VERSION ""
NS_ :

BS_:

BU_: Controls

BO_ 1408 CONTROL_MODE: 1 Controls
  SG_ State_name : 0|8@1- (1,0) [0|255] "" Controls

BO_ 1410 Motor_Precharge_Enable: 1 Controls
  SG_ Motor_Precharge_enable : 0|8@1+ (1,0) [0|255] "" Controls

BO_ 1408 Control_Mode: 1 Controls

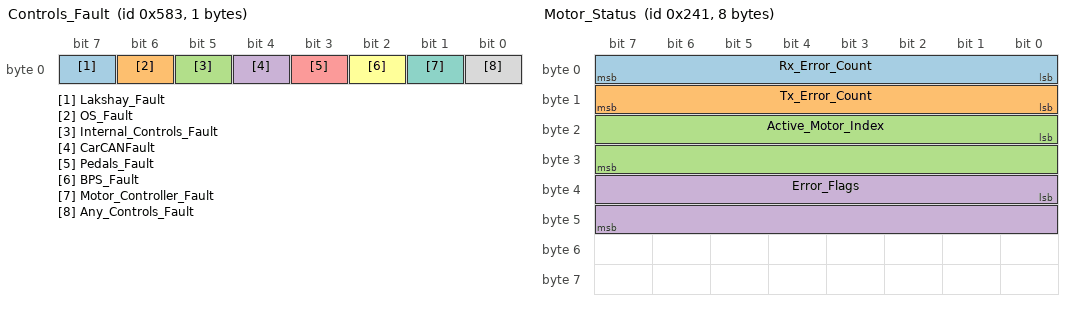
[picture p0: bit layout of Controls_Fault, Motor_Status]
BO_ 1411 Controls_Fault: 1 Controls
  SG_ Lakshay_Fault : 7|1@0+ (1,0) [0|1] "" Controls
  SG_ OS_Fault : 6|1@0+ (1,0) [0|1] "" Controls
  SG_ Internal_Controls_Fault : 5|1@0+ (1,0) [0|1] "" Controls
  SG_ CarCANFault : 4|1@0+ (1,0) [0|1] "" Controls
  SG_ Pedals_Fault : 3|1@0+ (1,0) [0|1] "" Controls
  SG_ BPS_Fault : 2|1@0+ (1,0) [0|1] "" Controls
  SG_ Motor_Controller_Fault : 1|1@0+ (1,0) [0|1] "" Controls
  SG_ Any_Controls_Fault : 0|1@0+ (1,0) [0|1] "" Controls

BO_ 1412 Motor_Controller_Safe: 1 Controls
  SG_ Motor_Safe : 1|1@1+ (1,0) [0|1] "" Controls
  SG_ Debug : 0|1@1+ (1,0) [0|1] "" Controls

BO_ 576 Motor_Controller_Identification: 8 Controls
  SG_ Device_Serial_Number : 32|32@1+ (1,0) [0|18446744073709552000] "" Controls
  SG_ Prohelion_ID : 0|32@1+ (1,0) [0|4294967295] "" Controls

BO_ 577 Motor_Status: 8 Controls
  SG_ Rx_Error_Count : 0|8@1+ (1,0) [0|255] "" Controls
  SG_ Tx_Error_Count : 8|8@1+ (1,0) [0|255] "" Controls
  SG_ Active_Motor_Index : 16|16@1+ (1,0) [0|65535] "" Controls
  SG_ Error_Flags : 32|16@1+ (1,0) [0|65535] "" Controls

BO_ 578 Motor_Controller_Bus: 8 Controls
  SG_ Bus_Current : 0|32@1+ (1,0) [0|4294967295] "A" Controls
  SG_ Bus_Voltage : 32|32@1+ (1,0) [0|4294967295] "V" Controls

BO_ 579 Velocity: 8 Controls
  SG_ Vehicle_Velocity : 0|32@1+ (1,0) [0|4294967295] "m/s" Controls
  SG_ Motor_Angular_Frequency : 32|32@1+ (1,0) [0|4294967295] "rpm" Controls

BO_ 580 Motor_Controller_Phase_Current: 8 Controls
  SG_ Phase_C_Current : 0|32@1+ (1,0) [0|4294967295] "A_rms" Controls
  SG_ Phase_B_Current : 32|32@1+ (1,0) [0|4294967295] "A_rms" Controls

BO_ 581 Motor_Voltage_Vector: 8 Controls
  SG_ Vd : 0|32@1+ (1,0) [0|4294967295] "V" Controls
  SG_ Vq : 32|32@1+ (1,0) [0|4294967295] "V" Controls

BO_ 582 Motor_Current_Vector: 8 Controls
  SG_ Id : 0|32@1+ (1,0) [0|4294967295] "A" Controls
  SG_ Iq : 32|32@1+ (1,0) [0|4294967295] "A" Controls

BO_ 583 Motor_BackEMF: 8 Controls
  SG_ Real_Component : 0|32@1+ (1,0) [0|4294967295] "V" Controls
  SG_ Peak_Phase_To_Neutral_Voltage : 32|32@1+ (1,0) [0|4294967295] "V" Controls

BO_ 584 Low_Voltage_Rail_Measurement: 8 Controls
  SG_ Actual_Voltage : 0|32@1+ (1,0) [0|4294967295] "V" Controls
  SG_ Reserved : 32|32@1+ (1,0) [0|4294967295] "" Controls

BO_ 585 DSP_Voltage_Rail_Measurement: 8 Controls
  SG_ Actual_Voltage_3_3V : 0|32@1+ (1,0) [0|4294967295] "V" Controls
  SG_ Actual_Voltage_1_9V : 32|32@1+ (1,0) [0|4294967295] "V" Controls

BO_ 587 Motor_Temperature: 8 Controls

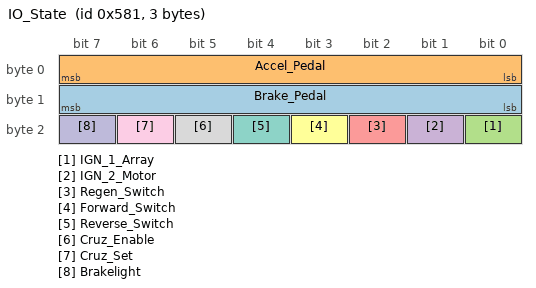
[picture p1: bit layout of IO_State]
BO_ 1409 IO_State: 3 Vector__XXX
  SG_ Brake_Pedal : 8|8@1+ (0,0) [0|0] "" Vector__XXX
  SG_ Accel_Pedal : 0|8@1+ (0,0) [0|0] "" Vector__XXX
  SG_ IGN_1_Array : 16|1@1+ (0,0) [0|0] "" Vector__XXX
  SG_ IGN_2_Motor : 17|1@1+ (0,0) [0|0] "" Vector__XXX
  SG_ Regen_Switch : 18|1@1+ (0,0) [0|0] "" Vector__XXX
  SG_ Forward_Switch : 19|1@1+ (0,0) [0|0] "" Vector__XXX
  SG_ Reverse_Switch : 20|1@1+ (0,0) [0|0] "" Vector__XXX
  SG_ Cruz_Enable : 21|1@1+ (0,0) [0|0] "" Vector__XXX
  SG_ Cruz_Set : 22|1@1+ (0,0) [0|0] "" Vector__XXX
  SG_ Brakelight : 23|1@1+ (0,0) [0|0] "" Vector__XXX
  SG_ Heat_Sink_Temperature : 0|32@
::contentReference[oaicite:0]{index=0}

CM_ SG_ 1412 Debug "for debug purposes";
